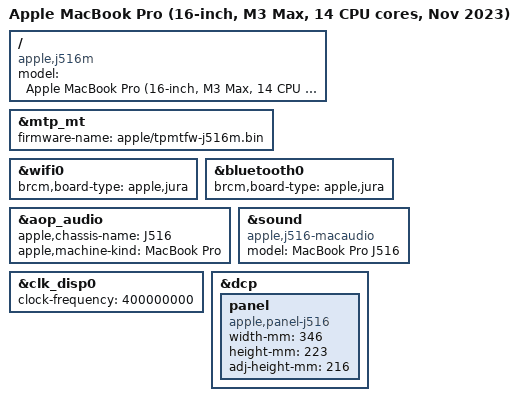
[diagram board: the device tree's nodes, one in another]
// SPDX-License-Identifier: GPL-2.0+ OR MIT
/*
 * MacBook Pro (16-inch, M3 Max, 14 CPU cores, Nov 2023)
 *
 * target-type: J516m
 *
 * Copyright The Asahi Linux Contributors
 */

/dts-v1/;

#include "t6034.dtsi"
#include "t6031-dcp.dtsi"
#include "t603x-j514-j516.dtsi"

/ {
	compatible = "apple,j516m", "apple,t6034", "apple,arm-platform";
	model = "Apple MacBook Pro (16-inch, M3 Max, 14 CPU cores, Nov 2023)";
};

&mtp_mt {
	firmware-name = "apple/tpmtfw-j516m.bin";
};

&wifi0 {
	brcm,board-type = "apple,jura";
};

&bluetooth0 {
	brcm,board-type = "apple,jura";
};

&aop_audio {
	apple,chassis-name = "J516";
	apple,machine-kind = "MacBook Pro";
};

&sound {
	compatible = "apple,j516-macaudio", "apple,j316-macaudio", "apple,macaudio";
	model = "MacBook Pro J516";
};

/*
 * J516M ADT confirms the J516C display register and interrupt layout.
 * External displays (dcpext, HDMI) are not described here yet.
 */
&clk_disp0 {
	/*
	 * Preserve the captured boot-clock metadata, as the J514M path does.
	 * Firmware warns that this is below its video clock;
	 * that warning is not proof of the programmed clock or a startup veto.
	 * The metadata does not qualify sustained power or thermal behavior.
	 */
	clock-frequency = <400000000>;
};

&dcp {
	panel {
		compatible = "apple,panel-j516", "apple,panel-mini-led", "apple,panel";
		width-mm = <346>;
		height-mm = <223>;
		adj-height-mm = <216>;
	};
};
